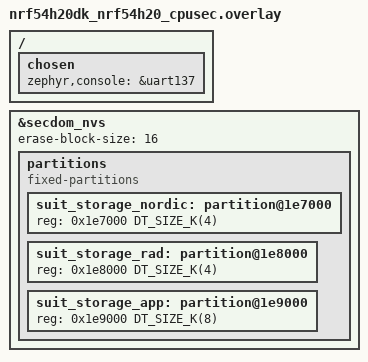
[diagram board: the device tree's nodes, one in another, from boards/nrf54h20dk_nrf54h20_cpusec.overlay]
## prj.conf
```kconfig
#
# Copyright (c) 2022 Nordic Semiconductor ASA
#
# SPDX-License-Identifier: LicenseRef-Nordic-5-Clause
#

CONFIG_ZTEST=y
CONFIG_ZTEST_NEW_API=y

CONFIG_SUIT=y
CONFIG_SUIT_UTILS=y
CONFIG_SUIT_STORAGE=y
CONFIG_SUIT_STORAGE_N_UPDATE_REGIONS=3
CONFIG_SUIT_METADATA=y

CONFIG_ZCBOR=y
CONFIG_ZCBOR_CANONICAL=y

CONFIG_FLASH=y
```

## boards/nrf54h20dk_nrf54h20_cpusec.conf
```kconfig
#
# Copyright (c) 2022 Nordic Semiconductor ASA
#
# SPDX-License-Identifier: LicenseRef-Nordic-5-Clause
#

CONFIG_NULL_POINTER_EXCEPTION_DETECTION_NONE=y
CONFIG_SERIAL=y
CONFIG_CONSOLE=y
CONFIG_UART_CONSOLE=y

# This test does not set 'IS_SECURE_DOMAIN_FW'. Hence, we need to enable the
# bare minimum configurations for running on bare metal Secure Domain.
CONFIG_SECDOM_UNIT_TEST_SUPPORT=y

# Logging and printk is using standard UART.
CONFIG_LOG_MODE_DEFERRED=y
CONFIG_LOG_BACKEND_UART=y
CONFIG_LOG_PRINTK=y
CONFIG_LOG_BUFFER_SIZE=8192
CONFIG_SOC_FLASH_NRF_MRAM_ONE_BYTE_WRITE_ACCESS=y

# nRF54H20 storage uses SHA-256 to protect MPI and NVVs:
CONFIG_SUIT_CRYPTO=y

# Configure MPI, so it matches the test-specific MCI
CONFIG_SUIT_MPI_GENERATE=y
CONFIG_SUIT_MPI_ROOT_CLASS_NAME="test_sample_root"
CONFIG_SUIT_MPI_ROOT_INDEPENDENT_UPDATE=y
CONFIG_SUIT_MPI_ROOT_SIGNATURE_CHECK_ENABLED_ON_UPDATE_AND_BOOT=y
CONFIG_SUIT_MPI_APP_LOCAL_1=y
CONFIG_SUIT_MPI_APP_LOCAL_1_CLASS_NAME="test_sample_app"
CONFIG_SUIT_MPI_APP_LOCAL_1_INDEPENDENT_UPDATE=n
CONFIG_SUIT_MPI_APP_LOCAL_1_SIGNATURE_CHECK_ENABLED_ON_UPDATE_AND_BOOT=y
```

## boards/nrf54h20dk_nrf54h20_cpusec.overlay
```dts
/*
 * Copyright (c) 2022 Nordic Semiconductor ASA
 *
 * SPDX-License-Identifier: LicenseRef-Nordic-5-Clause
 */

/ {
	chosen {
		zephyr,console = &uart137;
	};
};

&secdom_nvs {
	erase-block-size = <16>;

	partitions {
		compatible = "fixed-partitions";
		#address-cells = <1>;
		#size-cells = <1>;

		/* Use the last 32 kB of SecDom SUIT NVM storage. */
		/* Use the first 4kB as area reserved for Secure domain. */
		suit_storage_nordic: partition@1e7000 {
			reg = <0x1e7000 DT_SIZE_K(4)>;
		};

		/* Use the next 4kB as area reserved for Radio domain. */
		suit_storage_rad: partition@1e8000 {
			reg = <0x1e8000 DT_SIZE_K(4)>;
		};

		/* Use the next 8kB as area reserved for Application domain. */
		suit_storage_app: partition@1e9000 {
			reg = <0x1e9000 DT_SIZE_K(8)>;
		};
	};
};
```

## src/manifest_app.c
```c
/*
 * Copyright (c) 2023 Nordic Semiconductor ASA
 *
 * SPDX-License-Identifier: LicenseRef-Nordic-5-Clause
 */

#include <stdint.h>
#include <stddef.h>

/** @brief SUIT envelope generated using the manifest/manifest_app.yaml input file.
 *
 * @details This envelope contains 256-byte random numbers attached as an integrated
 *          payload and fetched directly into the memory-mapped region during install step.
 *          The envelope has been signed using the manifest/key_private.pem key.
 *
 * @note Please use the manifest_common/regenerate.sh script for regenerating payloads.
 */
uint8_t manifest_app_buf[] = {
	0xD8, 0x6B, 0xA4, 0x02, 0x58, 0x7A, 0x82, 0x58, 0x24, 0x82, 0x2F, 0x58, 0x20, 0x26, 0x04,
	0x04, 0xCF, 0x3A, 0xA5, 0x6E, 0xBA, 0x4D, 0xA9, 0xD5, 0xBE, 0xE4, 0x6D, 0x27, 0x33, 0xF3,
	0xD5, 0x4A, 0xD5, 0xE6, 0x72, 0x1E, 0x46, 0xEE, 0x58, 0x93, 0xB6, 0xDC, 0x4D, 0x2C, 0x93,
	0x58, 0x51, 0xD2, 0x84, 0x4A, 0xA2, 0x01, 0x26, 0x04, 0x45, 0x1A, 0x7F, 0xFF, 0xFF, 0xE0,
	0xA0, 0xF6, 0x58, 0x40, 0xE6, 0x16, 0xF7, 0x59, 0x93, 0xF2, 0x48, 0x68, 0x0B, 0xFE, 0x47,
	0x81, 0x10, 0x58, 0x96, 0xCB, 0xAD, 0x0A, 0xE5, 0x9D, 0x82, 0x74, 0xAD, 0x8B, 0x5F, 0x4C,
	0xCD, 0x32, 0xF4, 0x75, 0x27, 0x15, 0xAD, 0x3E, 0xC9, 0x71, 0x08, 0xAB, 0xAF, 0xCA, 0xD9,
	0x9B, 0x9B, 0x5B, 0x48, 0x1B, 0x60, 0x4D, 0xD6, 0xD3, 0xF2, 0x4A, 0x1B, 0x76, 0x56, 0xB6,
	0xEE, 0xF5, 0x41, 0x4D, 0x64, 0x14, 0x9D, 0x34, 0x03, 0x58, 0xDB, 0xA8, 0x01, 0x01, 0x02,
	0x01, 0x03, 0x58, 0x70, 0xA2, 0x02, 0x81, 0x84, 0x44, 0x63, 0x4D, 0x45, 0x4D, 0x41, 0x02,
	0x45, 0x1A, 0x0E, 0x0A, 0xA0, 0x00, 0x45, 0x1A, 0x00, 0x07, 0xF8, 0x00, 0x04, 0x58, 0x56,
	0x86, 0x14, 0xA4, 0x01, 0x50, 0x76, 0x17, 0xDA, 0xA5, 0x71, 0xFD, 0x5A, 0x85, 0x8F, 0x94,
	0xE2, 0x8D, 0x73, 0x5C, 0xE9, 0xF4, 0x02, 0x50, 0x08, 0xC1, 0xB5, 0x99, 0x55, 0xE8, 0x5F,
	0xBC, 0x9E, 0x76, 0x7B, 0xC2, 0x9C, 0xE1, 0xB0, 0x4D, 0x03, 0x58, 0x24, 0x82, 0x2F, 0x58,
	0x20, 0x5F, 0xC3, 0x54, 0xBF, 0x8E, 0x8C, 0x50, 0xFB, 0x4F, 0xBC, 0x2C, 0xFA, 0xEB, 0x04,
	0x53, 0x41, 0xC9, 0x80, 0x6D, 0xEA, 0xBD, 0xCB, 0x41, 0x54, 0xFB, 0x79, 0xCC, 0xA4, 0xF0,
	0xC9, 0x8C, 0x12, 0x0E, 0x19, 0x01, 0x00, 0x01, 0x0F, 0x02, 0x0F, 0x07, 0x43, 0x82, 0x03,
	0x0F, 0x09, 0x43, 0x82, 0x17, 0x02, 0x11, 0x52, 0x86, 0x14, 0xA1, 0x15, 0x69, 0x23, 0x66,
	0x69, 0x6C, 0x65, 0x2E, 0x62, 0x69, 0x6E, 0x15, 0x02, 0x03, 0x0F, 0x17, 0x82, 0x2F, 0x58,
	0x20, 0xD5, 0x91, 0xFC, 0x52, 0x92, 0x3A, 0x98, 0x8F, 0x6C, 0x59, 0x25, 0x62, 0x4E, 0xE5,
	0x27, 0x56, 0xA5, 0x90, 0x5B, 0x6C, 0xC4, 0x6C, 0x4B, 0x6A, 0xF6, 0xBA, 0x68, 0xD5, 0x83,
	0x53, 0xD2, 0x59, 0x05, 0x82, 0x4C, 0x6B, 0x49, 0x4E, 0x53, 0x54, 0x4C, 0x44, 0x5F, 0x4D,
	0x46, 0x53, 0x54, 0x50, 0x08, 0xC1, 0xB5, 0x99, 0x55, 0xE8, 0x5F, 0xBC, 0x9E, 0x76, 0x7B,
	0xC2, 0x9C, 0xE1, 0xB0, 0x4D, 0x17, 0x58, 0x97, 0xA1, 0x84, 0x44, 0x63, 0x4D, 0x45, 0x4D,
	0x41, 0x02, 0x45, 0x1A, 0x0E, 0x0A, 0xA0, 0x00, 0x45, 0x1A, 0x00, 0x07, 0xF8, 0x00, 0xA6,
	0x01, 0x78, 0x18, 0x4E, 0x6F, 0x72, 0x64, 0x69, 0x63, 0x20, 0x53, 0x65, 0x6D, 0x69, 0x63,
	0x6F, 0x6E, 0x64, 0x75, 0x63, 0x74, 0x6F, 0x72, 0x20, 0x41, 0x53, 0x41, 0x02, 0x6F, 0x6E,
	0x52, 0x46, 0x35, 0x34, 0x48, 0x32, 0x30, 0x5F, 0x63, 0x70, 0x75, 0x61, 0x70, 0x70, 0x03,
	0x6E, 0x6E, 0x6F, 0x72, 0x64, 0x69, 0x63, 0x73, 0x65, 0x6D, 0x69, 0x2E, 0x63, 0x6F, 0x6D,
	0x04, 0x78, 0x1D, 0x54, 0x68, 0x65, 0x20, 0x6E, 0x52, 0x46, 0x35, 0x34, 0x48, 0x32, 0x30,
	0x20, 0x61, 0x70, 0x70, 0x6C, 0x69, 0x63, 0x61, 0x74, 0x69, 0x6F, 0x6E, 0x20, 0x63, 0x6F,
	0x72, 0x65, 0x05, 0x78, 0x1A, 0x53, 0x61, 0x6D, 0x70, 0x6C, 0x65, 0x20, 0x61, 0x70, 0x70,
	0x6C, 0x69, 0x63, 0x61, 0x74, 0x69, 0x6F, 0x6E, 0x20, 0x63, 0x6F, 0x72, 0x65, 0x20, 0x46,
	0x57, 0x06, 0x66, 0x76, 0x31, 0x2E, 0x30, 0x2E, 0x30, 0x69, 0x23, 0x66, 0x69, 0x6C, 0x65,
	0x2E, 0x62, 0x69, 0x6E, 0x59, 0x01, 0x00, 0xC7, 0x9C, 0xAB, 0x9D, 0xE8, 0x33, 0x7F, 0x30,
	0x14, 0xEB, 0xAC, 0x02, 0xAF, 0x26, 0x01, 0x5E, 0x80, 0x6D, 0x88, 0xA1, 0xDB, 0x11, 0xA7,
	0x31, 0xDF, 0xA6, 0xEC, 0xCB, 0x9B, 0x48, 0x0D, 0xC8, 0x34, 0x40, 0x6D, 0x30, 0x86, 0x7D,
	0xE8, 0x1B, 0xEC, 0x3C, 0xF5, 0x40, 0xD0, 0x48, 0x18, 0x82, 0x11, 0x9D, 0x7C, 0x3F, 0x6C,
	0xE5, 0x8F, 0xF1, 0xD3, 0x5D, 0xE1, 0x51, 0xF7, 0x6A, 0x0F, 0xAF, 0x0B, 0xBD, 0x4C, 0x5F,
	0xA5, 0x34, 0x1A, 0x66, 0xDB, 0x22, 0xEC, 0x63, 0xED, 0x4B, 0xAB, 0xC7, 0xC8, 0xF7, 0x59,
	0xD8, 0xD6, 0x9E, 0xEC, 0x71, 0x1B, 0x24, 0x20, 0xB9, 0xAE, 0xE1, 0x3B, 0xFC, 0xAE, 0xB8,
	0x77, 0xAC, 0xA4, 0x57, 0x34, 0x97, 0x84, 0x4F, 0x58, 0xD5, 0x68, 0x08, 0x6F, 0xE3, 0x9C,
	0x7E, 0x1B, 0xD7, 0x38, 0x22, 0x98, 0x48, 0xF8, 0x7A, 0x67, 0xB2, 0xD9, 0xAC, 0xC5, 0x34,
	0xC1, 0x27, 0x82, 0x8E, 0x42, 0x79, 0x84, 0x21, 0x37, 0x4C, 0x41, 0x4A, 0x0F, 0xE2, 0x7F,
	0xA0, 0x6A, 0x19, 0x13, 0x3D, 0x52, 0x22, 0x7F, 0xD6, 0x2F, 0x71, 0x12, 0x76, 0xAB, 0x25,
	0x9C, 0xFC, 0x67, 0x08, 0x03, 0x7C, 0xDB, 0x18, 0xE6, 0x45, 0xF8, 0x99, 0xC2, 0x9E, 0x2C,
	0xE3, 0x9B, 0x25, 0xA9, 0x7B, 0x09, 0xFF, 0x00, 0x57, 0x26, 0x08, 0x0A, 0x11, 0x42, 0xCF,
	0x82, 0xA2, 0x6B, 0x2A, 0x99, 0xF9, 0x71, 0x9D, 0x14, 0x19, 0x5C, 0x5C, 0x78, 0x31, 0x60,
	0x42, 0x4A, 0x18, 0x1F, 0xEC, 0x78, 0x6A, 0x9A, 0x7C, 0x4F, 0xCF, 0xE8, 0x5A, 0x29, 0x65,
	0xCD, 0x01, 0x3B, 0x6D, 0x53, 0xBB, 0xC6, 0xDB, 0xDA, 0xD5, 0x8F, 0xF7, 0xF4, 0xD9, 0xB9,
	0x0A, 0x03, 0x4B, 0xFF, 0x33, 0xAB, 0x3B, 0xC5, 0xAF, 0xD0, 0xB8, 0x2C, 0x0F, 0x6A, 0xA9,
	0x11, 0xB0, 0xE8, 0x57, 0x8C, 0x92, 0x53, 0x81};

const size_t manifest_app_len = sizeof(manifest_app_buf);
```

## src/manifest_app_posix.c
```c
/*
 * Copyright (c) 2023 Nordic Semiconductor ASA
 *
 * SPDX-License-Identifier: LicenseRef-Nordic-5-Clause
 */

#include <stdint.h>
#include <stddef.h>

/** @brief SUIT envelope generated using the manifest/manifest_app_posix.yaml input file.
 *
 * @details This envelope contains 256-byte random numbers attached as an integrated
 *          payload and fetched directly into the memory-mapped region during install step.
 *          The envelope has been signed using the manifest/key_private.pem key.
 *
 * @note Please use the manifest_common/regenerate.sh script for regenerating payloads.
 */
uint8_t manifest_app_posix_buf[] = {
	0xD8, 0x6B, 0xA4, 0x02, 0x58, 0x7A, 0x82, 0x58, 0x24, 0x82, 0x2F, 0x58, 0x20, 0xC2, 0xEE,
	0x56, 0x00, 0xE9, 0x08, 0x9C, 0xCD, 0x62, 0xE4, 0xD9, 0x36, 0x00, 0xE2, 0x42, 0xCD, 0xC4,
	0x9F, 0xE4, 0x0F, 0xCC, 0x01, 0x60, 0x7F, 0x4B, 0x40, 0xE3, 0xB4, 0x28, 0x45, 0x53, 0xA8,
	0x58, 0x51, 0xD2, 0x84, 0x4A, 0xA2, 0x01, 0x26, 0x04, 0x45, 0x1A, 0x7F, 0xFF, 0xFF, 0xE0,
	0xA0, 0xF6, 0x58, 0x40, 0xB5, 0x86, 0xB1, 0x56, 0x1C, 0x38, 0x2F, 0x12, 0x99, 0xDC, 0x83,
	0x70, 0xA7, 0x53, 0xE2, 0x68, 0xA9, 0xBA, 0x4E, 0xEA, 0x91, 0xB0, 0xF3, 0x99, 0x4C, 0x9D,
	0xDF, 0x53, 0xDC, 0x9D, 0x22, 0x95, 0x53, 0xC6, 0x70, 0x27, 0xFF, 0x2C, 0xDB, 0xE7, 0x56,
	0x43, 0xAF, 0x40, 0x76, 0x87, 0x2C, 0x28, 0xF0, 0xA6, 0x54, 0x96, 0x4D, 0xA5, 0x49, 0x46,
	0x24, 0x2B, 0x59, 0x07, 0xCB, 0xC0, 0x63, 0x4B, 0x03, 0x58, 0xD9, 0xA8, 0x01, 0x01, 0x02,
	0x01, 0x03, 0x58, 0x6E, 0xA2, 0x02, 0x81, 0x84, 0x44, 0x63, 0x4D, 0x45, 0x4D, 0x41, 0x00,
	0x45, 0x1A, 0x00, 0x08, 0x00, 0x00, 0x43, 0x19, 0x10, 0x00, 0x04, 0x58, 0x56, 0x86, 0x14,
	0xA4, 0x01, 0x50, 0x76, 0x17, 0xDA, 0xA5, 0x71, 0xFD, 0x5A, 0x85, 0x8F, 0x94, 0xE2, 0x8D,
	0x73, 0x5C, 0xE9, 0xF4, 0x02, 0x50, 0x56, 0xDC, 0x9A, 0x14, 0x28, 0xD8, 0x52, 0xD3, 0xBD,
	0x62, 0xE7, 0x7A, 0x08, 0xBC, 0x8B, 0x91, 0x03, 0x58, 0x24, 0x82, 0x2F, 0x58, 0x20, 0x5F,
	0xC3, 0x54, 0xBF, 0x8E, 0x8C, 0x50, 0xFB, 0x4F, 0xBC, 0x2C, 0xFA, 0xEB, 0x04, 0x53, 0x41,
	0xC9, 0x80, 0x6D, 0xEA, 0xBD, 0xCB, 0x41, 0x54, 0xFB, 0x79, 0xCC, 0xA4, 0xF0, 0xC9, 0x8C,
	0x12, 0x0E, 0x19, 0x01, 0x00, 0x01, 0x0F, 0x02, 0x0F, 0x07, 0x43, 0x82, 0x03, 0x0F, 0x09,
	0x43, 0x82, 0x17, 0x02, 0x11, 0x52, 0x86, 0x14, 0xA1, 0x15, 0x69, 0x23, 0x66, 0x69, 0x6C,
	0x65, 0x2E, 0x62, 0x69, 0x6E, 0x15, 0x02, 0x03, 0x0F, 0x17, 0x82, 0x2F, 0x58, 0x20, 0x60,
	0xA8, 0x0D, 0xFD, 0xD4, 0xBF, 0x59, 0x42, 0x7E, 0x92, 0x7C, 0xA6, 0x93, 0x58, 0x63, 0xE1,
	0xF6, 0x04, 0x9A, 0x50, 0xE5, 0x0E, 0xB6, 0xF5, 0x3B, 0x81, 0x67, 0x29, 0x53, 0x14, 0xA7,
	0x9A, 0x05, 0x82, 0x4C, 0x6B, 0x49, 0x4E, 0x53, 0x54, 0x4C, 0x44, 0x5F, 0x4D, 0x46, 0x53,
	0x54, 0x50, 0x56, 0xDC, 0x9A, 0x14, 0x28, 0xD8, 0x52, 0xD3, 0xBD, 0x62, 0xE7, 0x7A, 0x08,
	0xBC, 0x8B, 0x91, 0x17, 0x58, 0x84, 0xA1, 0x84, 0x44, 0x63, 0x4D, 0x45, 0x4D, 0x41, 0x00,
	0x45, 0x1A, 0x00, 0x08, 0x00, 0x00, 0x43, 0x19, 0x10, 0x00, 0xA6, 0x01, 0x78, 0x18, 0x4E,
	0x6F, 0x72, 0x64, 0x69, 0x63, 0x20, 0x53, 0x65, 0x6D, 0x69, 0x63, 0x6F, 0x6E, 0x64, 0x75,
	0x63, 0x74, 0x6F, 0x72, 0x20, 0x41, 0x53, 0x41, 0x02, 0x65, 0x70, 0x6F, 0x73, 0x69, 0x78,
	0x03, 0x6E, 0x6E, 0x6F, 0x72, 0x64, 0x69, 0x63, 0x73, 0x65, 0x6D, 0x69, 0x2E, 0x63, 0x6F,
	0x6D, 0x04, 0x75, 0x54, 0x68, 0x65, 0x20, 0x50, 0x4F, 0x53, 0x49, 0x58, 0x20, 0x61, 0x70,
	0x70, 0x6C, 0x69, 0x63, 0x61, 0x74, 0x69, 0x6F, 0x6E, 0x05, 0x78, 0x1C, 0x53, 0x61, 0x6D,
	0x70, 0x6C, 0x65, 0x20, 0x61, 0x70, 0x70, 0x6C, 0x69, 0x63, 0x61, 0x74, 0x69, 0x6F, 0x6E,
	0x20, 0x66, 0x6F, 0x72, 0x20, 0x50, 0x4F, 0x53, 0x49, 0x58, 0x06, 0x66, 0x76, 0x31, 0x2E,
	0x30, 0x2E, 0x30, 0x69, 0x23, 0x66, 0x69, 0x6C, 0x65, 0x2E, 0x62, 0x69, 0x6E, 0x59, 0x01,
	0x00, 0xC7, 0x9C, 0xAB, 0x9D, 0xE8, 0x33, 0x7F, 0x30, 0x14, 0xEB, 0xAC, 0x02, 0xAF, 0x26,
	0x01, 0x5E, 0x80, 0x6D, 0x88, 0xA1, 0xDB, 0x11, 0xA7, 0x31, 0xDF, 0xA6, 0xEC, 0xCB, 0x9B,
	0x48, 0x0D, 0xC8, 0x34, 0x40, 0x6D, 0x30, 0x86, 0x7D, 0xE8, 0x1B, 0xEC, 0x3C, 0xF5, 0x40,
	0xD0, 0x48, 0x18, 0x82, 0x11, 0x9D, 0x7C, 0x3F, 0x6C, 0xE5, 0x8F, 0xF1, 0xD3, 0x5D, 0xE1,
	0x51, 0xF7, 0x6A, 0x0F, 0xAF, 0x0B, 0xBD, 0x4C, 0x5F, 0xA5, 0x34, 0x1A, 0x66, 0xDB, 0x22,
	0xEC, 0x63, 0xED, 0x4B, 0xAB, 0xC7, 0xC8, 0xF7, 0x59, 0xD8, 0xD6, 0x9E, 0xEC, 0x71, 0x1B,
	0x24, 0x20, 0xB9, 0xAE, 0xE1, 0x3B, 0xFC, 0xAE, 0xB8, 0x77, 0xAC, 0xA4, 0x57, 0x34, 0x97,
	0x84, 0x4F, 0x58, 0xD5, 0x68, 0x08, 0x6F, 0xE3, 0x9C, 0x7E, 0x1B, 0xD7, 0x38, 0x22, 0x98,
	0x48, 0xF8, 0x7A, 0x67, 0xB2, 0xD9, 0xAC, 0xC5, 0x34, 0xC1, 0x27, 0x82, 0x8E, 0x42, 0x79,
	0x84, 0x21, 0x37, 0x4C, 0x41, 0x4A, 0x0F, 0xE2, 0x7F, 0xA0, 0x6A, 0x19, 0x13, 0x3D, 0x52,
	0x22, 0x7F, 0xD6, 0x2F, 0x71, 0x12, 0x76, 0xAB, 0x25, 0x9C, 0xFC, 0x67, 0x08, 0x03, 0x7C,
	0xDB, 0x18, 0xE6, 0x45, 0xF8, 0x99, 0xC2, 0x9E, 0x2C, 0xE3, 0x9B, 0x25, 0xA9, 0x7B, 0x09,
	0xFF, 0x00, 0x57, 0x26, 0x08, 0x0A, 0x11, 0x42, 0xCF, 0x82, 0xA2, 0x6B, 0x2A, 0x99, 0xF9,
	0x71, 0x9D, 0x14, 0x19, 0x5C, 0x5C, 0x78, 0x31, 0x60, 0x42, 0x4A, 0x18, 0x1F, 0xEC, 0x78,
	0x6A, 0x9A, 0x7C, 0x4F, 0xCF, 0xE8, 0x5A, 0x29, 0x65, 0xCD, 0x01, 0x3B, 0x6D, 0x53, 0xBB,
	0xC6, 0xDB, 0xDA, 0xD5, 0x8F, 0xF7, 0xF4, 0xD9, 0xB9, 0x0A, 0x03, 0x4B, 0xFF, 0x33, 0xAB,
	0x3B, 0xC5, 0xAF, 0xD0, 0xB8, 0x2C, 0x0F, 0x6A, 0xA9, 0x11, 0xB0, 0xE8, 0x57, 0x8C, 0x92,
	0x53, 0x81};

const size_t manifest_app_posix_len = sizeof(manifest_app_posix_buf);
```

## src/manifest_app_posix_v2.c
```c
/*
 * Copyright (c) 2024 Nordic Semiconductor ASA
 *
 * SPDX-License-Identifier: LicenseRef-Nordic-5-Clause
 */

#include <stdint.h>
#include <stddef.h>

/** @brief SUIT envelope generated using the manifest/manifest_app_posix_v2.yaml input file.
 *
 * @details This envelope contains 256-byte random numbers attached as an integrated
 *          payload and fetched directly into the memory-mapped region during install step.
 *          The envelope has been signed using the manifest/key_private.pem key.
 *
 * @note Please use the manifest_common/regenerate.sh script for regenerating payloads.
 */
uint8_t manifest_app_posix_v2_buf[] = {
	0xD8, 0x6B, 0xA4, 0x02, 0x58, 0x7A, 0x82, 0x58, 0x24, 0x82, 0x2F, 0x58, 0x20, 0x9F, 0x97,
	0x6D, 0xE9, 0x7D, 0xEE, 0x2C, 0x67, 0xD3, 0xEF, 0xB1, 0x20, 0xA7, 0x6E, 0xDA, 0x0C, 0x98,
	0x9A, 0xD9, 0xC3, 0x14, 0xF9, 0xF7, 0x6F, 0xB4, 0xD6, 0xEB, 0xAF, 0x9E, 0x83, 0x88, 0x5E,
	0x58, 0x51, 0xD2, 0x84, 0x4A, 0xA2, 0x01, 0x26, 0x04, 0x45, 0x1A, 0x7F, 0xFF, 0xFF, 0xE0,
	0xA0, 0xF6, 0x58, 0x40, 0xB2, 0xC4, 0xEE, 0xCC, 0xBE, 0x3B, 0x85, 0xD3, 0x99, 0x4B, 0x2F,
	0xDA, 0xA2, 0x01, 0x49, 0xEE, 0x57, 0x65, 0xE7, 0x1B, 0x2D, 0x48, 0x2B, 0x8B, 0x41, 0xCD,
	0x45, 0x42, 0x6F, 0xBA, 0x9E, 0xC0, 0x97, 0x2D, 0x23, 0x81, 0x76, 0x55, 0xC7, 0xAD, 0x8A,
	0xDA, 0xBD, 0x25, 0x11, 0x15, 0xF7, 0x00, 0x7F, 0x0D, 0x77, 0x45, 0x49, 0xC7, 0x19, 0x74,
	0xF8, 0xDE, 0x25, 0x9E, 0xF1, 0x19, 0x13, 0x45, 0x03, 0x58, 0xD9, 0xA8, 0x01, 0x01, 0x02,
	0x02, 0x03, 0x58, 0x6E, 0xA2, 0x02, 0x81, 0x84, 0x44, 0x63, 0x4D, 0x45, 0x4D, 0x41, 0x00,
	0x45, 0x1A, 0x00, 0x08, 0x00, 0x00, 0x43, 0x19, 0x10, 0x00, 0x04, 0x58, 0x56, 0x86, 0x14,
	0xA4, 0x01, 0x50, 0x76, 0x17, 0xDA, 0xA5, 0x71, 0xFD, 0x5A, 0x85, 0x8F, 0x94, 0xE2, 0x8D,
	0x73, 0x5C, 0xE9, 0xF4, 0x02, 0x50, 0x5B, 0x46, 0x9F, 0xD1, 0x90, 0xEE, 0x53, 0x9C, 0xA3,
	0x18, 0x68, 0x1B, 0x03, 0x69, 0x5E, 0x36, 0x03, 0x58, 0x24, 0x82, 0x2F, 0x58, 0x20, 0x5F,
	0xC3, 0x54, 0xBF, 0x8E, 0x8C, 0x50, 0xFB, 0x4F, 0xBC, 0x2C, 0xFA, 0xEB, 0x04, 0x53, 0x41,
	0xC9, 0x80, 0x6D, 0xEA, 0xBD, 0xCB, 0x41, 0x54, 0xFB, 0x79, 0xCC, 0xA4, 0xF0, 0xC9, 0x8C,
	0x12, 0x0E, 0x19, 0x01, 0x00, 0x01, 0x0F, 0x02, 0x0F, 0x07, 0x43, 0x82, 0x03, 0x0F, 0x09,
	0x43, 0x82, 0x17, 0x02, 0x11, 0x52, 0x86, 0x14, 0xA1, 0x15, 0x69, 0x23, 0x66, 0x69, 0x6C,
	0x65, 0x2E, 0x62, 0x69, 0x6E, 0x15, 0x02, 0x03, 0x0F, 0x17, 0x82, 0x2F, 0x58, 0x20, 0x60,
	0xA8, 0x0D, 0xFD, 0xD4, 0xBF, 0x59, 0x42, 0x7E, 0x92, 0x7C, 0xA6, 0x93, 0x58, 0x63, 0xE1,
	0xF6, 0x04, 0x9A, 0x50, 0xE5, 0x0E, 0xB6, 0xF5, 0x3B, 0x81, 0x67, 0x29, 0x53, 0x14, 0xA7,
	0x9A, 0x05, 0x82, 0x4C, 0x6B, 0x49, 0x4E, 0x53, 0x54, 0x4C, 0x44, 0x5F, 0x4D, 0x46, 0x53,
	0x54, 0x50, 0x5B, 0x46, 0x9F, 0xD1, 0x90, 0xEE, 0x53, 0x9C, 0xA3, 0x18, 0x68, 0x1B, 0x03,
	0x69, 0x5E, 0x36, 0x17, 0x58, 0x84, 0xA1, 0x84, 0x44, 0x63, 0x4D, 0x45, 0x4D, 0x41, 0x00,
	0x45, 0x1A, 0x00, 0x08, 0x00, 0x00, 0x43, 0x19, 0x10, 0x00, 0xA6, 0x01, 0x78, 0x18, 0x4E,
	0x6F, 0x72, 0x64, 0x69, 0x63, 0x20, 0x53, 0x65, 0x6D, 0x69, 0x63, 0x6F, 0x6E, 0x64, 0x75,
	0x63, 0x74, 0x6F, 0x72, 0x20, 0x41, 0x53, 0x41, 0x02, 0x65, 0x70, 0x6F, 0x73, 0x69, 0x78,
	0x03, 0x6E, 0x6E, 0x6F, 0x72, 0x64, 0x69, 0x63, 0x73, 0x65, 0x6D, 0x69, 0x2E, 0x63, 0x6F,
	0x6D, 0x04, 0x75, 0x54, 0x68, 0x65, 0x20, 0x50, 0x4F, 0x53, 0x49, 0x58, 0x20, 0x61, 0x70,
	0x70, 0x6C, 0x69, 0x63, 0x61, 0x74, 0x69, 0x6F, 0x6E, 0x05, 0x78, 0x1C, 0x53, 0x61, 0x6D,
	0x70, 0x6C, 0x65, 0x20, 0x61, 0x70, 0x70, 0x6C, 0x69, 0x63, 0x61, 0x74, 0x69, 0x6F, 0x6E,
	0x20, 0x66, 0x6F, 0x72, 0x20, 0x50, 0x4F, 0x53, 0x49, 0x58, 0x06, 0x66, 0x76, 0x31, 0x2E,
	0x30, 0x2E, 0x30, 0x69, 0x23, 0x66, 0x69, 0x6C, 0x65, 0x2E, 0x62, 0x69, 0x6E, 0x59, 0x01,
	0x00, 0xC7, 0x9C, 0xAB, 0x9D, 0xE8, 0x33, 0x7F, 0x30, 0x14, 0xEB, 0xAC, 0x02, 0xAF, 0x26,
	0x01, 0x5E, 0x80, 0x6D, 0x88, 0xA1, 0xDB, 0x11, 0xA7, 0x31, 0xDF, 0xA6, 0xEC, 0xCB, 0x9B,
	0x48, 0x0D, 0xC8, 0x34, 0x40, 0x6D, 0x30, 0x86, 0x7D, 0xE8, 0x1B, 0xEC, 0x3C, 0xF5, 0x40,
	0xD0, 0x48, 0x18, 0x82, 0x11, 0x9D, 0x7C, 0x3F, 0x6C, 0xE5, 0x8F, 0xF1, 0xD3, 0x5D, 0xE1,
	0x51, 0xF7, 0x6A, 0x0F, 0xAF, 0x0B, 0xBD, 0x4C, 0x5F, 0xA5, 0x34, 0x1A, 0x66, 0xDB, 0x22,
	0xEC, 0x63, 0xED, 0x4B, 0xAB, 0xC7, 0xC8, 0xF7, 0x59, 0xD8, 0xD6, 0x9E, 0xEC, 0x71, 0x1B,
	0x24, 0x20, 0xB9, 0xAE, 0xE1, 0x3B, 0xFC, 0xAE, 0xB8, 0x77, 0xAC, 0xA4, 0x57, 0x34, 0x97,
	0x84, 0x4F, 0x58, 0xD5, 0x68, 0x08, 0x6F, 0xE3, 0x9C, 0x7E, 0x1B, 0xD7, 0x38, 0x22, 0x98,
	0x48, 0xF8, 0x7A, 0x67, 0xB2, 0xD9, 0xAC, 0xC5, 0x34, 0xC1, 0x27, 0x82, 0x8E, 0x42, 0x79,
	0x84, 0x21, 0x37, 0x4C, 0x41, 0x4A, 0x0F, 0xE2, 0x7F, 0xA0, 0x6A, 0x19, 0x13, 0x3D, 0x52,
	0x22, 0x7F, 0xD6, 0x2F, 0x71, 0x12, 0x76, 0xAB, 0x25, 0x9C, 0xFC, 0x67, 0x08, 0x03, 0x7C,
	0xDB, 0x18, 0xE6, 0x45, 0xF8, 0x99, 0xC2, 0x9E, 0x2C, 0xE3, 0x9B, 0x25, 0xA9, 0x7B, 0x09,
	0xFF, 0x00, 0x57, 0x26, 0x08, 0x0A, 0x11, 0x42, 0xCF, 0x82, 0xA2, 0x6B, 0x2A, 0x99, 0xF9,
	0x71, 0x9D, 0x14, 0x19, 0x5C, 0x5C, 0x78, 0x31, 0x60, 0x42, 0x4A, 0x18, 0x1F, 0xEC, 0x78,
	0x6A, 0x9A, 0x7C, 0x4F, 0xCF, 0xE8, 0x5A, 0x29, 0x65, 0xCD, 0x01, 0x3B, 0x6D, 0x53, 0xBB,
	0xC6, 0xDB, 0xDA, 0xD5, 0x8F, 0xF7, 0xF4, 0xD9, 0xB9, 0x0A, 0x03, 0x4B, 0xFF, 0x33, 0xAB,
	0x3B, 0xC5, 0xAF, 0xD0, 0xB8, 0x2C, 0x0F, 0x6A, 0xA9, 0x11, 0xB0, 0xE8, 0x57, 0x8C, 0x92,
	0x53, 0x81};

const size_t manifest_app_posix_v2_len = sizeof(manifest_app_posix_v2_buf);
```

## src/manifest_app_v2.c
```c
/*
 * Copyright (c) 2023 Nordic Semiconductor ASA
 *
 * SPDX-License-Identifier: LicenseRef-Nordic-5-Clause
 */

#include <stdint.h>
#include <stddef.h>

/** @brief SUIT envelope generated using the manifest/manifest_app_v2.yaml input file.
 *
 * @details This envelope contains 256-byte random numbers attached as an integrated
 *          payload and fetched directly into the memory-mapped region during install step.
 *          The envelope has been signed using the manifest/key_private.pem key.
 *
 * @note Please use the manifest_common/regenerate.sh script for regenerating payloads.
 */
uint8_t manifest_app_v2_buf[] = {
	0xD8, 0x6B, 0xA2, 0x02, 0x58, 0x7A, 0x82, 0x58, 0x24, 0x82, 0x2F, 0x58, 0x20, 0x45, 0xCC,
	0xC3, 0x8F, 0xB7, 0xEA, 0x5A, 0x86, 0xC9, 0xEA, 0xA1, 0x73, 0x44, 0x25, 0xDB, 0x4A, 0x43,
	0x90, 0x66, 0x14, 0x88, 0x16, 0x55, 0x08, 0xEA, 0xB5, 0xEA, 0x94, 0x35, 0xD8, 0x49, 0x32,
	0x58, 0x51, 0xD2, 0x84, 0x4A, 0xA2, 0x01, 0x26, 0x04, 0x45, 0x1A, 0x7F, 0xFF, 0xFF, 0xE0,
	0xA0, 0xF6, 0x58, 0x40, 0x7B, 0x03, 0x3F, 0x04, 0xB8, 0xA5, 0xA8, 0xAE, 0x1F, 0x79, 0xC2,
	0xA5, 0xB6, 0x1D, 0x26, 0xD0, 0xF3, 0x5D, 0xBB, 0x93, 0x8B, 0x5C, 0xDF, 0xE8, 0xCD, 0xAE,
	0x61, 0x4C, 0x89, 0x46, 0xC9, 0x01, 0xCB, 0x63, 0x90, 0x7B, 0xD6, 0x37, 0xFB, 0x1E, 0x35,
	0xA7, 0xF6, 0x39, 0xC6, 0xE3, 0x79, 0x70, 0x49, 0x0C, 0x8D, 0x1C, 0x40, 0x58, 0xAD, 0x9A,
	0x61, 0x7E, 0x38, 0xE6, 0xC0, 0xB7, 0x64, 0x8C, 0x03, 0x58, 0xB6, 0xA7, 0x01, 0x01, 0x02,
	0x02, 0x03, 0x58, 0x70, 0xA2, 0x02, 0x81, 0x84, 0x44, 0x63, 0x4D, 0x45, 0x4D, 0x41, 0x02,
	0x45, 0x1A, 0x0E, 0x0A, 0xA0, 0x00, 0x45, 0x1A, 0x00, 0x07, 0xF8, 0x00, 0x04, 0x58, 0x56,
	0x86, 0x14, 0xA4, 0x01, 0x50, 0x76, 0x17, 0xDA, 0xA5, 0x71, 0xFD, 0x5A, 0x85, 0x8F, 0x94,
	0xE2, 0x8D, 0x73, 0x5C, 0xE9, 0xF4, 0x02, 0x50, 0x08, 0xC1, 0xB5, 0x99, 0x55, 0xE8, 0x5F,
	0xBC, 0x9E, 0x76, 0x7B, 0xC2, 0x9C, 0xE1, 0xB0, 0x4D, 0x03, 0x58, 0x24, 0x82, 0x2F, 0x58,
	0x20, 0x5F, 0xC3, 0x54, 0xBF, 0x8E, 0x8C, 0x50, 0xFB, 0x4F, 0xBC, 0x2C, 0xFA, 0xEB, 0x04,
	0x53, 0x41, 0xC9, 0x80, 0x6D, 0xEA, 0xBD, 0xCB, 0x41, 0x54, 0xFB, 0x79, 0xCC, 0xA4, 0xF0,
	0xC9, 0x8C, 0x12, 0x0E, 0x19, 0x01, 0x00, 0x01, 0x0F, 0x02, 0x0F, 0x07, 0x43, 0x82, 0x03,
	0x0F, 0x09, 0x43, 0x82, 0x17, 0x02, 0x11, 0x52, 0x86, 0x14, 0xA1, 0x15, 0x69, 0x23, 0x66,
	0x69, 0x6C, 0x65, 0x2E, 0x62, 0x69, 0x6E, 0x15, 0x02, 0x03, 0x0F, 0x05, 0x82, 0x4C, 0x6B,
	0x49, 0x4E, 0x53, 0x54, 0x4C, 0x44, 0x5F, 0x4D, 0x46, 0x53, 0x54, 0x50, 0x08, 0xC1, 0xB5,
	0x99, 0x55, 0xE8, 0x5F, 0xBC, 0x9E, 0x76, 0x7B, 0xC2, 0x9C, 0xE1, 0xB0, 0x4D};

const size_t manifest_app_v2_len = sizeof(manifest_app_v2_buf);
```

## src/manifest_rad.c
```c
/*
 * Copyright (c) 2023 Nordic Semiconductor ASA
 *
 * SPDX-License-Identifier: LicenseRef-Nordic-5-Clause
 */

#include <stdint.h>
#include <stddef.h>

/** @brief SUIT envelope generated using the manifest/manifest_rad.yaml input file.
 *
 * @details This envelope contains 256-byte random numbers attached as an integrated
 *          payload and fetched directly into the memory-mapped region during install step.
 *          The envelope has been signed using the manifest/key_private.pem key.
 *
 * @note Please use the manifest_common/regenerate.sh script for regenerating payloads.
 */
uint8_t manifest_rad_buf[] = {
	0xD8, 0x6B, 0xA4, 0x02, 0x58, 0x7A, 0x82, 0x58, 0x24, 0x82, 0x2F, 0x58, 0x20, 0x28, 0x0C,
	0xD6, 0x6B, 0x67, 0xA0, 0x0C, 0xC6, 0x35, 0x04, 0xC2, 0x01, 0x65, 0x4B, 0xB4, 0x9E, 0x07,
	0x92, 0xC3, 0xDA, 0x0C, 0x43, 0x6B, 0xDD, 0x45, 0x79, 0x14, 0xCD, 0xF1, 0x96, 0x1B, 0x27,
	0x58, 0x51, 0xD2, 0x84, 0x4A, 0xA2, 0x01, 0x26, 0x04, 0x45, 0x1A, 0x7F, 0xFF, 0xFF, 0xE0,
	0xA0, 0xF6, 0x58, 0x40, 0x48, 0x9A, 0x46, 0xE2, 0x1F, 0xCD, 0x6B, 0xFF, 0x1A, 0x1D, 0x42,
	0x9E, 0xA8, 0x8D, 0x34, 0xF4, 0x33, 0x2B, 0x8F, 0xB9, 0x08, 0x5D, 0xEA, 0xB1, 0x61, 0x86,
	0x74, 0xE4, 0x2C, 0x2C, 0x14, 0x90, 0x8A, 0x62, 0x86, 0xE0, 0x63, 0x25, 0xEF, 0x50, 0x12,
	0xCD, 0x6C, 0x9F, 0x7E, 0xAE, 0x62, 0x71, 0x4F, 0xDE, 0x9D, 0xD6, 0xF7, 0x55, 0xB3, 0x55,
	0xEF, 0xDD, 0x55, 0xDE, 0x69, 0x8A, 0x20, 0x95, 0x03, 0x58, 0xDB, 0xA8, 0x01, 0x01, 0x02,
	0x01, 0x03, 0x58, 0x70, 0xA2, 0x02, 0x81, 0x84, 0x44, 0x63, 0x4D, 0x45, 0x4D, 0x41, 0x03,
	0x45, 0x1A, 0x0E, 0x05, 0x40, 0x00, 0x45, 0x1A, 0x00, 0x05, 0x58, 0x00, 0x04, 0x58, 0x56,
	0x86, 0x14, 0xA4, 0x01, 0x50, 0x76, 0x17, 0xDA, 0xA5, 0x71, 0xFD, 0x5A, 0x85, 0x8F, 0x94,
	0xE2, 0x8D, 0x73, 0x5C, 0xE9, 0xF4, 0x02, 0x50, 0x81, 0x6A, 0xA0, 0xA0, 0xAF, 0x11, 0x5E,
	0xF2, 0x85, 0x8A, 0xFE, 0xB6, 0x68, 0xB2, 0xE9, 0xC9, 0x03, 0x58, 0x24, 0x82, 0x2F, 0x58,
	0x20, 0x5F, 0xC3, 0x54, 0xBF, 0x8E, 0x8C, 0x50, 0xFB, 0x4F, 0xBC, 0x2C, 0xFA, 0xEB, 0x04,
	0x53, 0x41, 0xC9, 0x80, 0x6D, 0xEA, 0xBD, 0xCB, 0x41, 0x54, 0xFB, 0x79, 0xCC, 0xA4, 0xF0,
	0xC9, 0x8C, 0x12, 0x0E, 0x19, 0x01, 0x00, 0x01, 0x0F, 0x02, 0x0F, 0x07, 0x43, 0x82, 0x03,
	0x0F, 0x09, 0x43, 0x82, 0x17, 0x02, 0x11, 0x52, 0x86, 0x14, 0xA1, 0x15, 0x69, 0x23, 0x66,
	0x69, 0x6C, 0x65, 0x2E, 0x62, 0x69, 0x6E, 0x15, 0x02, 0x03, 0x0F, 0x17, 0x82, 0x2F, 0x58,
	0x20, 0x3E, 0xD0, 0x66, 0x23, 0xC1, 0xD6, 0x23, 0x1F, 0x50, 0xCF, 0x53, 0xE5, 0x36, 0xE9,
	0xA5, 0x50, 0x02, 0xD9, 0x74, 0x57, 0x5C, 0x9F, 0x5F, 0x77, 0xF3, 0x22, 0x13, 0x03, 0xE9,
	0x7B, 0x4A, 0x0F, 0x05, 0x82, 0x4C, 0x6B, 0x49, 0x4E, 0x53, 0x54, 0x4C, 0x44, 0x5F, 0x4D,
	0x46, 0x53, 0x54, 0x50, 0x81, 0x6A, 0xA0, 0xA0, 0xAF, 0x11, 0x5E, 0xF2, 0x85, 0x8A, 0xFE,
	0xB6, 0x68, 0xB2, 0xE9, 0xC9, 0x17, 0x58, 0x89, 0xA1, 0x84, 0x44, 0x63, 0x4D, 0x45, 0x4D,
	0x41, 0x03, 0x45, 0x1A, 0x0E, 0x05, 0x40, 0x00, 0x45, 0x1A, 0x00, 0x05, 0x58, 0x00, 0xA6,
	0x01, 0x78, 0x18, 0x4E, 0x6F, 0x72, 0x64, 0x69, 0x63, 0x20, 0x53, 0x65, 0x6D, 0x69, 0x63,
	0x6F, 0x6E, 0x64, 0x75, 0x63, 0x74, 0x6F, 0x72, 0x20, 0x41, 0x53, 0x41, 0x02, 0x6F, 0x6E,
	0x52, 0x46, 0x35, 0x34, 0x48, 0x32, 0x30, 0x5F, 0x63, 0x70, 0x75, 0x72, 0x61, 0x64, 0x03,
	0x6E, 0x6E, 0x6F, 0x72, 0x64, 0x69, 0x63, 0x73, 0x65, 0x6D, 0x69, 0x2E, 0x63, 0x6F, 0x6D,
	0x04, 0x77, 0x54, 0x68, 0x65, 0x20, 0x6E, 0x52, 0x46, 0x35, 0x34, 0x48, 0x32, 0x30, 0x20,
	0x72, 0x61, 0x64, 0x69, 0x6F, 0x20, 0x63, 0x6F, 0x72, 0x65, 0x05, 0x74, 0x53, 0x61, 0x6D,
	0x70, 0x6C, 0x65, 0x20, 0x72, 0x61, 0x64, 0x69, 0x6F, 0x20, 0x63, 0x6F, 0x72, 0x65, 0x20,
	0x46, 0x57, 0x06, 0x66, 0x76, 0x31, 0x2E, 0x30, 0x2E, 0x30, 0x69, 0x23, 0x66, 0x69, 0x6C,
	0x65, 0x2E, 0x62, 0x69, 0x6E, 0x59, 0x01, 0x00, 0xC7, 0x9C, 0xAB, 0x9D, 0xE8, 0x33, 0x7F,
	0x30, 0x14, 0xEB, 0xAC, 0x02, 0xAF, 0x26, 0x01, 0x5E, 0x80, 0x6D, 0x88, 0xA1, 0xDB, 0x11,
	0xA7, 0x31, 0xDF, 0xA6, 0xEC, 0xCB, 0x9B, 0x48, 0x0D, 0xC8, 0x34, 0x40, 0x6D, 0x30, 0x86,
	0x7D, 0xE8, 0x1B, 0xEC, 0x3C, 0xF5, 0x40, 0xD0, 0x48, 0x18, 0x82, 0x11, 0x9D, 0x7C, 0x3F,
	0x6C, 0xE5, 0x8F, 0xF1, 0xD3, 0x5D, 0xE1, 0x51, 0xF7, 0x6A, 0x0F, 0xAF, 0x0B, 0xBD, 0x4C,
	0x5F, 0xA5, 0x34, 0x1A, 0x66, 0xDB, 0x22, 0xEC, 0x63, 0xED, 0x4B, 0xAB, 0xC7, 0xC8, 0xF7,
	0x59, 0xD8, 0xD6, 0x9E, 0xEC, 0x71, 0x1B, 0x24, 0x20, 0xB9, 0xAE, 0xE1, 0x3B, 0xFC, 0xAE,
	0xB8, 0x77, 0xAC, 0xA4, 0x57, 0x34, 0x97, 0x84, 0x4F, 0x58, 0xD5, 0x68, 0x08, 0x6F, 0xE3,
	0x9C, 0x7E, 0x1B, 0xD7, 0x38, 0x22, 0x98, 0x48, 0xF8, 0x7A, 0x67, 0xB2, 0xD9, 0xAC, 0xC5,
	0x34, 0xC1, 0x27, 0x82, 0x8E, 0x42, 0x79, 0x84, 0x21, 0x37, 0x4C, 0x41, 0x4A, 0x0F, 0xE2,
	0x7F, 0xA0, 0x6A, 0x19, 0x13, 0x3D, 0x52, 0x22, 0x7F, 0xD6, 0x2F, 0x71, 0x12, 0x76, 0xAB,
	0x25, 0x9C, 0xFC, 0x67, 0x08, 0x03, 0x7C, 0xDB, 0x18, 0xE6, 0x45, 0xF8, 0x99, 0xC2, 0x9E,
	0x2C, 0xE3, 0x9B, 0x25, 0xA9, 0x7B, 0x09, 0xFF, 0x00, 0x57, 0x26, 0x08, 0x0A, 0x11, 0x42,
	0xCF, 0x82, 0xA2, 0x6B, 0x2A, 0x99, 0xF9, 0x71, 0x9D, 0x14, 0x19, 0x5C, 0x5C, 0x78, 0x31,
	0x60, 0x42, 0x4A, 0x18, 0x1F, 0xEC, 0x78, 0x6A, 0x9A, 0x7C, 0x4F, 0xCF, 0xE8, 0x5A, 0x29,
	0x65, 0xCD, 0x01, 0x3B, 0x6D, 0x53, 0xBB, 0xC6, 0xDB, 0xDA, 0xD5, 0x8F, 0xF7, 0xF4, 0xD9,
	0xB9, 0x0A, 0x03, 0x4B, 0xFF, 0x33, 0xAB, 0x3B, 0xC5, 0xAF, 0xD0, 0xB8, 0x2C, 0x0F, 0x6A,
	0xA9, 0x11, 0xB0, 0xE8, 0x57, 0x8C, 0x92, 0x53, 0x81};

const size_t manifest_rad_len = sizeof(manifest_rad_buf);
```

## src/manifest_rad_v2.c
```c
/*
 * Copyright (c) 2023 Nordic Semiconductor ASA
 *
 * SPDX-License-Identifier: LicenseRef-Nordic-5-Clause
 */

#include <stdint.h>
#include <stddef.h>

/** @brief SUIT envelope generated using the manifest/manifest_rad_v2.yaml input file.
 *
 * @details This envelope contains 256-byte random numbers attached as an integrated
 *          payload and fetched directly into the memory-mapped region during install step.
 *          The envelope has been signed using the manifest/key_private.pem key.
 *
 * @note Please use the manifest_common/regenerate.sh script for regenerating payloads.
 */
uint8_t manifest_rad_v2_buf[] = {
	0xD8, 0x6B, 0xA2, 0x02, 0x58, 0x7A, 0x82, 0x58, 0x24, 0x82, 0x2F, 0x58, 0x20, 0x52, 0xDA,
	0xDD, 0xDF, 0xDA, 0x18, 0xFF, 0x08, 0x14, 0xAA, 0x45, 0x84, 0xC2, 0xE6, 0x71, 0x3B, 0x5F,
	0xD5, 0x8E, 0x23, 0xF3, 0x7C, 0xE8, 0xBB, 0x8A, 0xF6, 0x72, 0xEE, 0x4A, 0xE6, 0x3C, 0x89,
	0x58, 0x51, 0xD2, 0x84, 0x4A, 0xA2, 0x01, 0x26, 0x04, 0x45, 0x1A, 0x7F, 0xFF, 0xFF, 0xE0,
	0xA0, 0xF6, 0x58, 0x40, 0x3F, 0xC1, 0x61, 0x9A, 0xAC, 0x92, 0x30, 0x09, 0x49, 0x26, 0x52,
	0x55, 0xAC, 0x46, 0xC7, 0x57, 0xC4, 0x1D, 0x84, 0x84, 0x2D, 0xA0, 0x5B, 0xEC, 0xAA, 0xF1,
	0x38, 0xB8, 0xB2, 0x5F, 0x90, 0x9B, 0x19, 0xD8, 0x05, 0xF9, 0x42, 0xFD, 0xEF, 0xA7, 0x42,
	0x31, 0xC9, 0x77, 0x34, 0x4D, 0x34, 0x46, 0x7F, 0xDE, 0x9B, 0xED, 0xDF, 0x93, 0xAF, 0x6F,
	0xA5, 0xE3, 0xCF, 0x2F, 0xE6, 0xB4, 0xEF, 0x62, 0x03, 0x58, 0xB6, 0xA7, 0x01, 0x01, 0x02,
	0x02, 0x03, 0x58, 0x70, 0xA2, 0x02, 0x81, 0x84, 0x44, 0x63, 0x4D, 0x45, 0x4D, 0x41, 0x03,
	0x45, 0x1A, 0x0E, 0x05, 0x40, 0x00, 0x45, 0x1A, 0x00, 0x05, 0x58, 0x00, 0x04, 0x58, 0x56,
	0x86, 0x14, 0xA4, 0x01, 0x50, 0x76, 0x17, 0xDA, 0xA5, 0x71, 0xFD, 0x5A, 0x85, 0x8F, 0x94,
	0xE2, 0x8D, 0x73, 0x5C, 0xE9, 0xF4, 0x02, 0x50, 0x81, 0x6A, 0xA0, 0xA0, 0xAF, 0x11, 0x5E,
	0xF2, 0x85, 0x8A, 0xFE, 0xB6, 0x68, 0xB2, 0xE9, 0xC9, 0x03, 0x58, 0x24, 0x82, 0x2F, 0x58,
	0x20, 0x5F, 0xC3, 0x54, 0xBF, 0x8E, 0x8C, 0x50, 0xFB, 0x4F, 0xBC, 0x2C, 0xFA, 0xEB, 0x04,
	0x53, 0x41, 0xC9, 0x80, 0x6D, 0xEA, 0xBD, 0xCB, 0x41, 0x54, 0xFB, 0x79, 0xCC, 0xA4, 0xF0,
	0xC9, 0x8C, 0x12, 0x0E, 0x19, 0x01, 0x00, 0x01, 0x0F, 0x02, 0x0F, 0x07, 0x43, 0x82, 0x03,
	0x0F, 0x09, 0x43, 0x82, 0x17, 0x02, 0x11, 0x52, 0x86, 0x14, 0xA1, 0x15, 0x69, 0x23, 0x66,
	0x69, 0x6C, 0x65, 0x2E, 0x62, 0x69, 0x6E, 0x15, 0x02, 0x03, 0x0F, 0x05, 0x82, 0x4C, 0x6B,
	0x49, 0x4E, 0x53, 0x54, 0x4C, 0x44, 0x5F, 0x4D, 0x46, 0x53, 0x54, 0x50, 0x81, 0x6A, 0xA0,
	0xA0, 0xAF, 0x11, 0x5E, 0xF2, 0x85, 0x8A, 0xFE, 0xB6, 0x68, 0xB2, 0xE9, 0xC9};

const size_t manifest_rad_v2_len = sizeof(manifest_rad_v2_buf);
```

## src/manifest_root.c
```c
/*
 * Copyright (c) 2023 Nordic Semiconductor ASA
 *
 * SPDX-License-Identifier: LicenseRef-Nordic-5-Clause
 */

#include <stdint.h>
#include <stddef.h>

/** @brief SUIT envelope generated using the manifest/manifest_root.yaml input file.
 *
 * @details This envelope contains 256-byte random numbers attached as an integrated
 *          payload and fetched directly into the memory-mapped region during install step.
 *          The envelope has been signed using the manifest/key_private.pem key.
 *
 * @note Please use the manifest_common/regenerate.sh script for regenerating payloads.
 */
uint8_t manifest_root_buf[] = {
	0xD8, 0x6B, 0xA5, 0x02, 0x58, 0x7A, 0x82, 0x58, 0x24, 0x82, 0x2F, 0x58, 0x20, 0x9C, 0x9F,
	0x5F, 0xA1, 0x5E, 0x25, 0xD6, 0x83, 0x2F, 0x50, 0x64, 0x49, 0x08, 0xA9, 0x69, 0x1C, 0xDD,
	0xF1, 0xD3, 0x9E, 0xF4, 0x75, 0xBA, 0x21, 0x38, 0x5E, 0x65, 0x55, 0x26, 0x5C, 0x2D, 0xB0,
	0x58, 0x51, 0xD2, 0x84, 0x4A, 0xA2, 0x01, 0x26, 0x04, 0x45, 0x1A, 0x7F, 0xFF, 0xFF, 0xE0,
	0xA0, 0xF6, 0x58, 0x40, 0xEE, 0xFD, 0xCA, 0x34, 0x1E, 0x61, 0x9E, 0xE9, 0xB4, 0x7E, 0x92,
	0xFD, 0x7C, 0xC2, 0xF6, 0x9D, 0xAE, 0x72, 0x41, 0x3D, 0xF1, 0x58, 0xAA, 0x06, 0x07, 0x33,
	0x56, 0xF2, 0x49, 0x61, 0xF3, 0x70, 0x5B, 0x9D, 0xFA, 0x1B, 0x6A, 0x62, 0x61, 0x99, 0xB5,
	0xBA, 0x38, 0x41, 0x64, 0xD5, 0x5F, 0xAE, 0xEB, 0xE3, 0x92, 0x21, 0x2E, 0x57, 0xED, 0x6B,
	0xC0, 0xBB, 0x8F, 0x6C, 0xF3, 0xB5, 0x1A, 0xD2, 0x03, 0x59, 0x01, 0x94, 0xA8, 0x01, 0x01,
	0x02, 0x01, 0x03, 0x58, 0xB3, 0xA3, 0x02, 0x83, 0x82, 0x4A, 0x69, 0x43, 0x41, 0x4E, 0x44,
	0x5F, 0x4D, 0x46, 0x53, 0x54, 0x41, 0x00, 0x82, 0x4C, 0x6B, 0x49, 0x4E, 0x53, 0x54, 0x4C,
	0x44, 0x5F, 0x4D, 0x46, 0x53, 0x54, 0x50, 0x81, 0x6A, 0xA0, 0xA0, 0xAF, 0x11, 0x5E, 0xF2,
	0x85, 0x8A, 0xFE, 0xB6, 0x68, 0xB2, 0xE9, 0xC9, 0x82, 0x4C, 0x6B, 0x49, 0x4E, 0x53, 0x54,
	0x4C, 0x44, 0x5F, 0x4D, 0x46, 0x53, 0x54, 0x50, 0x08, 0xC1, 0xB5, 0x99, 0x55, 0xE8, 0x5F,
	0xBC, 0x9E, 0x76, 0x7B, 0xC2, 0x9C, 0xE1, 0xB0, 0x4D, 0x04, 0x58, 0x59, 0x8E, 0x0C, 0x01,
	0x14, 0xA2, 0x01, 0x50, 0x76, 0x17, 0xDA, 0xA5, 0x71, 0xFD, 0x5A, 0x85, 0x8F, 0x94, 0xE2,
	0x8D, 0x73, 0x5C, 0xE9, 0xF4, 0x02, 0x50, 0x81, 0x6A, 0xA0, 0xA0, 0xAF, 0x11, 0x5E, 0xF2,
	0x85, 0x8A, 0xFE, 0xB6, 0x68, 0xB2, 0xE9, 0xC9, 0x0C, 0x02, 0x14, 0xA2, 0x01, 0x50, 0x76,
	0x17, 0xDA, 0xA5, 0x71, 0xFD, 0x5A, 0x85, 0x8F, 0x94, 0xE2, 0x8D, 0x73, 0x5C, 0xE9, 0xF4,
	0x02, 0x50, 0x08, 0xC1, 0xB5, 0x99, 0x55, 0xE8, 0x5F, 0xBC, 0x9E, 0x76, 0x7B, 0xC2, 0x9C,
	0xE1, 0xB0, 0x4D, 0x0C, 0x82, 0x01, 0x02, 0x01, 0x0F, 0x02, 0x0F, 0x01, 0xA3, 0x00, 0xA0,
	0x01, 0xA0, 0x02, 0xA0, 0x07, 0x49, 0x86, 0x0C, 0x82, 0x01, 0x02, 0x07, 0x0F, 0x0B, 0x0F,
	0x09, 0x49, 0x86, 0x0C, 0x82, 0x01, 0x02, 0x07, 0x0F, 0x0B, 0x0F, 0x11, 0x58, 0x7B, 0x96,
	0x0C, 0x00, 0x14, 0xA2, 0x15, 0x69, 0x23, 0x72, 0x61, 0x64, 0x2E, 0x73, 0x75, 0x69, 0x74,
	0x03, 0x58, 0x24, 0x82, 0x2F, 0x58, 0x20, 0xC0, 0xDB, 0x75, 0x51, 0x28, 0xE7, 0x72, 0xC5,
	0x8D, 0x2B, 0x4E, 0xDD, 0xC3, 0x94, 0x7D, 0xF8, 0x91, 0x38, 0xAE, 0xA1, 0xD3, 0xDA, 0xB2,
	0xFF, 0x71, 0xB1, 0xF5, 0x45, 0x96, 0x9E, 0x9D, 0x16, 0x15, 0x02, 0x03, 0x0F, 0x07, 0x0F,
	0x0B, 0x0F, 0x14, 0xA2, 0x15, 0x69, 0x23, 0x61, 0x70, 0x70, 0x2E, 0x73, 0x75, 0x69, 0x74,
	0x03, 0x58, 0x24, 0x82, 0x2F, 0x58, 0x20, 0x48, 0xAB, 0x74, 0x29, 0x46, 0xC8, 0x75, 0x32,
	0x91, 0xCF, 0xA9, 0xF8, 0xEB, 0x9F, 0x63, 0x73, 0x7C, 0xFE, 0x78, 0x21, 0x1E, 0xA1, 0x32,
	0x40, 0x58, 0x6F, 0xF2, 0x76, 0xD2, 0x9F, 0x32, 0x6D, 0x15, 0x02, 0x03, 0x0F, 0x07, 0x0F,
	0x0B, 0x0F, 0x17, 0x82, 0x2F, 0x58, 0x20, 0x6B, 0x66, 0xF8, 0x5A, 0xF6, 0xEB, 0xFF, 0xA6,
	0xB3, 0x1E, 0x46, 0x36, 0x1F, 0x18, 0xFC, 0x2A, 0x6B, 0xE9, 0xB6, 0x41, 0x8D, 0x60, 0xC2,
	0x7F, 0x31, 0xEA, 0xF9, 0xA3, 0xE4, 0xCD, 0xC4, 0x65, 0x05, 0x82, 0x4C, 0x6B, 0x49, 0x4E,
	0x53, 0x54, 0x4C, 0x44, 0x5F, 0x4D, 0x46, 0x53, 0x54, 0x50, 0x3F, 0x6A, 0x3A, 0x4D, 0xCD,
	0xFA, 0x58, 0xC5, 0xAC, 0xCE, 0xF9, 0xF5, 0x84, 0xC4, 0x11, 0x24, 0x17, 0x58, 0x80, 0xA1,
	0x82, 0x4A, 0x69, 0x43, 0x41, 0x4E, 0x44, 0x5F, 0x4D, 0x46, 0x53, 0x54, 0x41, 0x00, 0xA6,
	0x01, 0x78, 0x18, 0x4E, 0x6F, 0x72, 0x64, 0x69, 0x63, 0x20, 0x53, 0x65, 0x6D, 0x69, 0x63,
	0x6F, 0x6E, 0x64, 0x75, 0x63, 0x74, 0x6F, 0x72, 0x20, 0x41, 0x53, 0x41, 0x02, 0x68, 0x6E,
	0x52, 0x46, 0x35, 0x34, 0x48, 0x32, 0x30, 0x03, 0x6E, 0x6E, 0x6F, 0x72, 0x64, 0x69, 0x63,
	0x73, 0x65, 0x6D, 0x69, 0x2E, 0x63, 0x6F, 0x6D, 0x04, 0x78, 0x1A, 0x54, 0x68, 0x65, 0x20,
	0x6E, 0x52, 0x46, 0x35, 0x34, 0x48, 0x32, 0x30, 0x20, 0x72, 0x6F, 0x6F, 0x74, 0x20, 0x6D,
	0x61, 0x6E, 0x69, 0x66, 0x65, 0x73, 0x74, 0x05, 0x74, 0x53, 0x61, 0x6D, 0x70, 0x6C, 0x65,
	0x20, 0x72, 0x6F, 0x6F, 0x74, 0x20, 0x6D, 0x61, 0x6E, 0x69, 0x66, 0x65, 0x73, 0x74, 0x06,
	0x66, 0x76, 0x31, 0x2E, 0x30, 0x2E, 0x30, 0x69, 0x23, 0x72, 0x61, 0x64, 0x2E, 0x73, 0x75,
	0x69, 0x74, 0x59, 0x02, 0xF7, 0xD8, 0x6B, 0xA4, 0x02, 0x58, 0x7A, 0x82, 0x58, 0x24, 0x82,
	0x2F, 0x58, 0x20, 0x28, 0x0C, 0xD6, 0x6B, 0x67, 0xA0, 0x0C, 0xC6, 0x35, 0x04, 0xC2, 0x01,
	0x65, 0x4B, 0xB4, 0x9E, 0x07, 0x92, 0xC3, 0xDA, 0x0C, 0x43, 0x6B, 0xDD, 0x45, 0x79, 0x14,
	0xCD, 0xF1, 0x96, 0x1B, 0x27, 0x58, 0x51, 0xD2, 0x84, 0x4A, 0xA2, 0x01, 0x26, 0x04, 0x45,
	0x1A, 0x7F, 0xFF, 0xFF, 0xE0, 0xA0, 0xF6, 0x58, 0x40, 0x48, 0x9A, 0x46, 0xE2, 0x1F, 0xCD,
	0x6B, 0xFF, 0x1A, 0x1D, 0x42, 0x9E, 0xA8, 0x8D, 0x34, 0xF4, 0x33, 0x2B, 0x8F, 0xB9, 0x08,
	0x5D, 0xEA, 0xB1, 0x61, 0x86, 0x74, 0xE4, 0x2C, 0x2C, 0x14, 0x90, 0x8A, 0x62, 0x86, 0xE0,
	0x63, 0x25, 0xEF, 0x50, 0x12, 0xCD, 0x6C, 0x9F, 0x7E, 0xAE, 0x62, 0x71, 0x4F, 0xDE, 0x9D,
	0xD6, 0xF7, 0x55, 0xB3, 0x55, 0xEF, 0xDD, 0x55, 0xDE, 0x69, 0x8A, 0x20, 0x95, 0x03, 0x58,
	0xDB, 0xA8, 0x01, 0x01, 0x02, 0x01, 0x03, 0x58, 0x70, 0xA2, 0x02, 0x81, 0x84, 0x44, 0x63,
	0x4D, 0x45, 0x4D, 0x41, 0x03, 0x45, 0x1A, 0x0E, 0x05, 0x40, 0x00, 0x45, 0x1A, 0x00, 0x05,
	0x58, 0x00, 0x04, 0x58, 0x56, 0x86, 0x14, 0xA4, 0x01, 0x50, 0x76, 0x17, 0xDA, 0xA5, 0x71,
	0xFD, 0x5A, 0x85, 0x8F, 0x94, 0xE2, 0x8D, 0x73, 0x5C, 0xE9, 0xF4, 0x02, 0x50, 0x81, 0x6A,
	0xA0, 0xA0, 0xAF, 0x11, 0x5E, 0xF2, 0x85, 0x8A, 0xFE, 0xB6, 0x68, 0xB2, 0xE9, 0xC9, 0x03,
	0x58, 0x24, 0x82, 0x2F, 0x58, 0x20, 0x5F, 0xC3, 0x54, 0xBF, 0x8E, 0x8C, 0x50, 0xFB, 0x4F,
	0xBC, 0x2C, 0xFA, 0xEB, 0x04, 0x53, 0x41, 0xC9, 0x80, 0x6D, 0xEA, 0xBD, 0xCB, 0x41, 0x54,
	0xFB, 0x79, 0xCC, 0xA4, 0xF0, 0xC9, 0x8C, 0x12, 0x0E, 0x19, 0x01, 0x00, 0x01, 0x0F, 0x02,
	0x0F, 0x07, 0x43, 0x82, 0x03, 0x0F, 0x09, 0x43, 0x82, 0x17, 0x02, 0x11, 0x52, 0x86, 0x14,
	0xA1, 0x15, 0x69, 0x23, 0x66, 0x69, 0x6C, 0x65, 0x2E, 0x62, 0x69, 0x6E, 0x15, 0x02, 0x03,
	0x0F, 0x17, 0x82, 0x2F, 0x58, 0x20, 0x3E, 0xD0, 0x66, 0x23, 0xC1, 0xD6, 0x23, 0x1F, 0x50,
	0xCF, 0x53, 0xE5, 0x36, 0xE9, 0xA5, 0x50, 0x02, 0xD9, 0x74, 0x57, 0x5C, 0x9F, 0x5F, 0x77,
	0xF3, 0x22, 0x13, 0x03, 0xE9, 0x7B, 0x4A, 0x0F, 0x05, 0x82, 0x4C, 0x6B, 0x49, 0x4E, 0x53,
	0x54, 0x4C, 0x44, 0x5F, 0x4D, 0x46, 0x53, 0x54, 0x50, 0x81, 0x6A, 0xA0, 0xA0, 0xAF, 0x11,
	0x5E, 0xF2, 0x85, 0x8A, 0xFE, 0xB6, 0x68, 0xB2, 0xE9, 0xC9, 0x17, 0x58, 0x89, 0xA1, 0x84,
	0x44, 0x63, 0x4D, 0x45, 0x4D, 0x41, 0x03, 0x45, 0x1A, 0x0E, 0x05, 0x40, 0x00, 0x45, 0x1A,
	0x00, 0x05, 0x58, 0x00, 0xA6, 0x01, 0x78, 0x18, 0x4E, 0x6F, 0x72, 0x64, 0x69, 0x63, 0x20,
	0x53, 0x65, 0x6D, 0x69, 0x63, 0x6F, 0x6E, 0x64, 0x75, 0x63, 0x74, 0x6F, 0x72, 0x20, 0x41,
	0x53, 0x41, 0x02, 0x6F, 0x6E, 0x52, 0x46, 0x35, 0x34, 0x48, 0x32, 0x30, 0x5F, 0x63, 0x70,
	0x75, 0x72, 0x61, 0x64, 0x03, 0x6E, 0x6E, 0x6F, 0x72, 0x64, 0x69, 0x63, 0x73, 0x65, 0x6D,
	0x69, 0x2E, 0x63, 0x6F, 0x6D, 0x04, 0x77, 0x54, 0x68, 0x65, 0x20, 0x6E, 0x52, 0x46, 0x35,
	0x34, 0x48, 0x32, 0x30, 0x20, 0x72, 0x61, 0x64, 0x69, 0x6F, 0x20, 0x63, 0x6F, 0x72, 0x65,
	0x05, 0x74, 0x53, 0x61, 0x6D, 0x70, 0x6C, 0x65, 0x20, 0x72, 0x61, 0x64, 0x69, 0x6F, 0x20,
	0x63, 0x6F, 0x72, 0x65, 0x20, 0x46, 0x57, 0x06, 0x66, 0x76, 0x31, 0x2E, 0x30, 0x2E, 0x30,
	0x69, 0x23, 0x66, 0x69, 0x6C, 0x65, 0x2E, 0x62, 0x69, 0x6E, 0x59, 0x01, 0x00, 0xC7, 0x9C,
	0xAB, 0x9D, 0xE8, 0x33, 0x7F, 0x30, 0x14, 0xEB, 0xAC, 0x02, 0xAF, 0x26, 0x01, 0x5E, 0x80,
	0x6D, 0x88, 0xA1, 0xDB, 0x11, 0xA7, 0x31, 0xDF, 0xA6, 0xEC, 0xCB, 0x9B, 0x48, 0x0D, 0xC8,
	0x34, 0x40, 0x6D, 0x30, 0x86, 0x7D, 0xE8, 0x1B, 0xEC, 0x3C, 0xF5, 0x40, 0xD0, 0x48, 0x18,
	0x82, 0x11, 0x9D, 0x7C, 0x3F, 0x6C, 0xE5, 0x8F, 0xF1, 0xD3, 0x5D, 0xE1, 0x51, 0xF7, 0x6A,
	0x0F, 0xAF, 0x0B, 0xBD, 0x4C, 0x5F, 0xA5, 0x34, 0x1A, 0x66, 0xDB, 0x22, 0xEC, 0x63, 0xED,
	0x4B, 0xAB, 0xC7, 0xC8, 0xF7, 0x59, 0xD8, 0xD6, 0x9E, 0xEC, 0x71, 0x1B, 0x24, 0x20, 0xB9,
	0xAE, 0xE1, 0x3B, 0xFC, 0xAE, 0xB8, 0x77, 0xAC, 0xA4, 0x57, 0x34, 0x97, 0x84, 0x4F, 0x58,
	0xD5, 0x68, 0x08, 0x6F, 0xE3, 0x9C, 0x7E, 0x1B, 0xD7, 0x38, 0x22, 0x98, 0x48, 0xF8, 0x7A,
	0x67, 0xB2, 0xD9, 0xAC, 0xC5, 0x34, 0xC1, 0x27, 0x82, 0x8E, 0x42, 0x79, 0x84, 0x21, 0x37,
	0x4C, 0x41, 0x4A, 0x0F, 0xE2, 0x7F, 0xA0, 0x6A, 0x19, 0x13, 0x3D, 0x52, 0x22, 0x7F, 0xD6,
	0x2F, 0x71, 0x12, 0x76, 0xAB, 0x25, 0x9C, 0xFC, 0x67, 0x08, 0x03, 0x7C, 0xDB, 0x18, 0xE6,
	0x45, 0xF8, 0x99, 0xC2, 0x9E, 0x2C, 0xE3, 0x9B, 0x25, 0xA9, 0x7B, 0x09, 0xFF, 0x00, 0x57,
	0x26, 0x08, 0x0A, 0x11, 0x42, 0xCF, 0x82, 0xA2, 0x6B, 0x2A, 0x99, 0xF9, 0x71, 0x9D, 0x14,
	0x19, 0x5C, 0x5C, 0x78, 0x31, 0x60, 0x42, 0x4A, 0x18, 0x1F, 0xEC, 0x78, 0x6A, 0x9A, 0x7C,
	0x4F, 0xCF, 0xE8, 0x5A, 0x29, 0x65, 0xCD, 0x01, 0x3B, 0x6D, 0x53, 0xBB, 0xC6, 0xDB, 0xDA,
	0xD5, 0x8F, 0xF7, 0xF4, 0xD9, 0xB9, 0x0A, 0x03, 0x4B, 0xFF, 0x33, 0xAB, 0x3B, 0xC5, 0xAF,
	0xD0, 0xB8, 0x2C, 0x0F, 0x6A, 0xA9, 0x11, 0xB0, 0xE8, 0x57, 0x8C, 0x92, 0x53, 0x81, 0x69,
	0x23, 0x61, 0x70, 0x70, 0x2E, 0x73, 0x75, 0x69, 0x74, 0x59, 0x03, 0x05, 0xD8, 0x6B, 0xA4,
	0x02, 0x58, 0x7A, 0x82, 0x58, 0x24, 0x82, 0x2F, 0x58, 0x20, 0x26, 0x04, 0x04, 0xCF, 0x3A,
	0xA5, 0x6E, 0xBA, 0x4D, 0xA9, 0xD5, 0xBE, 0xE4, 0x6D, 0x27, 0x33, 0xF3, 0xD5, 0x4A, 0xD5,
	0xE6, 0x72, 0x1E, 0x46, 0xEE, 0x58, 0x93, 0xB6, 0xDC, 0x4D, 0x2C, 0x93, 0x58, 0x51, 0xD2,
	0x84, 0x4A, 0xA2, 0x01, 0x26, 0x04, 0x45, 0x1A, 0x7F, 0xFF, 0xFF, 0xE0, 0xA0, 0xF6, 0x58,
	0x40, 0xE6, 0x16, 0xF7, 0x59, 0x93, 0xF2, 0x48, 0x68, 0x0B, 0xFE, 0x47, 0x81, 0x10, 0x58,
	0x96, 0xCB, 0xAD, 0x0A, 0xE5, 0x9D, 0x82, 0x74, 0xAD, 0x8B, 0x5F, 0x4C, 0xCD, 0x32, 0xF4,
	0x75, 0x27, 0x15, 0xAD, 0x3E, 0xC9, 0x71, 0x08, 0xAB, 0xAF, 0xCA, 0xD9, 0x9B, 0x9B, 0x5B,
	0x48, 0x1B, 0x60, 0x4D, 0xD6, 0xD3, 0xF2, 0x4A, 0x1B, 0x76, 0x56, 0xB6, 0xEE, 0xF5, 0x41,
	0x4D, 0x64, 0x14, 0x9D, 0x34, 0x03, 0x58, 0xDB, 0xA8, 0x01, 0x01, 0x02, 0x01, 0x03, 0x58,
	0x70, 0xA2, 0x02, 0x81, 0x84, 0x44, 0x63, 0x4D, 0x45, 0x4D, 0x41, 0x02, 0x45, 0x1A, 0x0E,
	0x0A, 0xA0, 0x00, 0x45, 0x1A, 0x00, 0x07, 0xF8, 0x00, 0x04, 0x58, 0x56, 0x86, 0x14, 0xA4,
	0x01, 0x50, 0x76, 0x17, 0xDA, 0xA5, 0x71, 0xFD, 0x5A, 0x85, 0x8F, 0x94, 0xE2, 0x8D, 0x73,
	0x5C, 0xE9, 0xF4, 0x02, 0x50, 0x08, 0xC1, 0xB5, 0x99, 0x55, 0xE8, 0x5F, 0xBC, 0x9E, 0x76,
	0x7B, 0xC2, 0x9C, 0xE1, 0xB0, 0x4D, 0x03, 0x58, 0x24, 0x82, 0x2F, 0x58, 0x20, 0x5F, 0xC3,
	0x54, 0xBF, 0x8E, 0x8C, 0x50, 0xFB, 0x4F, 0xBC, 0x2C, 0xFA, 0xEB, 0x04, 0x53, 0x41, 0xC9,
	0x80, 0x6D, 0xEA, 0xBD, 0xCB, 0x41, 0x54, 0xFB, 0x79, 0xCC, 0xA4, 0xF0, 0xC9, 0x8C, 0x12,
	0x0E, 0x19, 0x01, 0x00, 0x01, 0x0F, 0x02, 0x0F, 0x07, 0x43, 0x82, 0x03, 0x0F, 0x09, 0x43,
	0x82, 0x17, 0x02, 0x11, 0x52, 0x86, 0x14, 0xA1, 0x15, 0x69, 0x23, 0x66, 0x69, 0x6C, 0x65,
	0x2E, 0x62, 0x69, 0x6E, 0x15, 0x02, 0x03, 0x0F, 0x17, 0x82, 0x2F, 0x58, 0x20, 0xD5, 0x91,
	0xFC, 0x52, 0x92, 0x3A, 0x98, 0x8F, 0x6C, 0x59, 0x25, 0x62, 0x4E, 0xE5, 0x27, 0x56, 0xA5,
	0x90, 0x5B, 0x6C, 0xC4, 0x6C, 0x4B, 0x6A, 0xF6, 0xBA, 0x68, 0xD5, 0x83, 0x53, 0xD2, 0x59,
	0x05, 0x82, 0x4C, 0x6B, 0x49, 0x4E, 0x53, 0x54, 0x4C, 0x44, 0x5F, 0x4D, 0x46, 0x53, 0x54,
	0x50, 0x08, 0xC1, 0xB5, 0x99, 0x55, 0xE8, 0x5F, 0xBC, 0x9E, 0x76, 0x7B, 0xC2, 0x9C, 0xE1,
	0xB0, 0x4D, 0x17, 0x58, 0x97, 0xA1, 0x84, 0x44, 0x63, 0x4D, 0x45, 0x4D, 0x41, 0x02, 0x45,
	0x1A, 0x0E, 0x0A, 0xA0, 0x00, 0x45, 0x1A, 0x00, 0x07, 0xF8, 0x00, 0xA6, 0x01, 0x78, 0x18,
	0x4E, 0x6F, 0x72, 0x64, 0x69, 0x63, 0x20, 0x53, 0x65, 0x6D, 0x69, 0x63, 0x6F, 0x6E, 0x64,
	0x75, 0x63, 0x74, 0x6F, 0x72, 0x20, 0x41, 0x53, 0x41, 0x02, 0x6F, 0x6E, 0x52, 0x46, 0x35,
	0x34, 0x48, 0x32, 0x30, 0x5F, 0x63, 0x70, 0x75, 0x61, 0x70, 0x70, 0x03, 0x6E, 0x6E, 0x6F,
	0x72, 0x64, 0x69, 0x63, 0x73, 0x65, 0x6D, 0x69, 0x2E, 0x63, 0x6F, 0x6D, 0x04, 0x78, 0x1D,
	0x54, 0x68, 0x65, 0x20, 0x6E, 0x52, 0x46, 0x35, 0x34, 0x48, 0x32, 0x30, 0x20, 0x61, 0x70,
	0x70, 0x6C, 0x69, 0x63, 0x61, 0x74, 0x69, 0x6F, 0x6E, 0x20, 0x63, 0x6F, 0x72, 0x65, 0x05,
	0x78, 0x1A, 0x53, 0x61, 0x6D, 0x70, 0x6C, 0x65, 0x20, 0x61, 0x70, 0x70, 0x6C, 0x69, 0x63,
	0x61, 0x74, 0x69, 0x6F, 0x6E, 0x20, 0x63, 0x6F, 0x72, 0x65, 0x20, 0x46, 0x57, 0x06, 0x66,
	0x76, 0x31, 0x2E, 0x30, 0x2E, 0x30, 0x69, 0x23, 0x66, 0x69, 0x6C, 0x65, 0x2E, 0x62, 0x69,
	0x6E, 0x59, 0x01, 0x00, 0xC7, 0x9C, 0xAB, 0x9D, 0xE8, 0x33, 0x7F, 0x30, 0x14, 0xEB, 0xAC,
	0x02, 0xAF, 0x26, 0x01, 0x5E, 0x80, 0x6D, 0x88, 0xA1, 0xDB, 0x11, 0xA7, 0x31, 0xDF, 0xA6,
	0xEC, 0xCB, 0x9B, 0x48, 0x0D, 0xC8, 0x34, 0x40, 0x6D, 0x30, 0x86, 0x7D, 0xE8, 0x1B, 0xEC,
	0x3C, 0xF5, 0x40, 0xD0, 0x48, 0x18, 0x82, 0x11, 0x9D, 0x7C, 0x3F, 0x6C, 0xE5, 0x8F, 0xF1,
	0xD3, 0x5D, 0xE1, 0x51, 0xF7, 0x6A, 0x0F, 0xAF, 0x0B, 0xBD, 0x4C, 0x5F, 0xA5, 0x34, 0x1A,
	0x66, 0xDB, 0x22, 0xEC, 0x63, 0xED, 0x4B, 0xAB, 0xC7, 0xC8, 0xF7, 0x59, 0xD8, 0xD6, 0x9E,
	0xEC, 0x71, 0x1B, 0x24, 0x20, 0xB9, 0xAE, 0xE1, 0x3B, 0xFC, 0xAE, 0xB8, 0x77, 0xAC, 0xA4,
	0x57, 0x34, 0x97, 0x84, 0x4F, 0x58, 0xD5, 0x68, 0x08, 0x6F, 0xE3, 0x9C, 0x7E, 0x1B, 0xD7,
	0x38, 0x22, 0x98, 0x48, 0xF8, 0x7A, 0x67, 0xB2, 0xD9, 0xAC, 0xC5, 0x34, 0xC1, 0x27, 0x82,
	0x8E, 0x42, 0x79, 0x84, 0x21, 0x37, 0x4C, 0x41, 0x4A, 0x0F, 0xE2, 0x7F, 0xA0, 0x6A, 0x19,
	0x13, 0x3D, 0x52, 0x22, 0x7F, 0xD6, 0x2F, 0x71, 0x12, 0x76, 0xAB, 0x25, 0x9C, 0xFC, 0x67,
	0x08, 0x03, 0x7C, 0xDB, 0x18, 0xE6, 0x45, 0xF8, 0x99, 0xC2, 0x9E, 0x2C, 0xE3, 0x9B, 0x25,
	0xA9, 0x7B, 0x09, 0xFF, 0x00, 0x57, 0x26, 0x08, 0x0A, 0x11, 0x42, 0xCF, 0x82, 0xA2, 0x6B,
	0x2A, 0x99, 0xF9, 0x71, 0x9D, 0x14, 0x19, 0x5C, 0x5C, 0x78, 0x31, 0x60, 0x42, 0x4A, 0x18,
	0x1F, 0xEC, 0x78, 0x6A, 0x9A, 0x7C, 0x4F, 0xCF, 0xE8, 0x5A, 0x29, 0x65, 0xCD, 0x01, 0x3B,
	0x6D, 0x53, 0xBB, 0xC6, 0xDB, 0xDA, 0xD5, 0x8F, 0xF7, 0xF4, 0xD9, 0xB9, 0x0A, 0x03, 0x4B,
	0xFF, 0x33, 0xAB, 0x3B, 0xC5, 0xAF, 0xD0, 0xB8, 0x2C, 0x0F, 0x6A, 0xA9, 0x11, 0xB0, 0xE8,
	0x57, 0x8C, 0x92, 0x53, 0x81};

const size_t manifest_root_len = sizeof(manifest_root_buf);
```

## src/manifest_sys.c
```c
/*
 * Copyright (c) 2023 Nordic Semiconductor ASA
 *
 * SPDX-License-Identifier: LicenseRef-Nordic-5-Clause
 */

#include <stdint.h>
#include <stddef.h>

/** @brief SUIT envelope generated using the manifest/manifest_sys.yaml input file.
 *
 * @details This envelope contains 256-byte random numbers attached as an integrated
 *          payload and fetched directly into the memory-mapped region during install step.
 *          The envelope has been signed using the manifest/key_private.pem key.
 *
 * @note Please use the manifest_common/regenerate.sh script for regenerating payloads.
 */
uint8_t manifest_sys_buf[] = {
	0xD8, 0x6B, 0xA4, 0x02, 0x58, 0x7A, 0x82, 0x58, 0x24, 0x82, 0x2F, 0x58, 0x20, 0x9C, 0xD0,
	0x4A, 0x63, 0x30, 0xDC, 0xCC, 0xBF, 0xD7, 0x41, 0x1F, 0x19, 0x47, 0x6B, 0xF3, 0x9A, 0xD1,
	0x85, 0x62, 0x2F, 0xDD, 0xD4, 0x21, 0x6A, 0x37, 0xD8, 0x30, 0xAC, 0x51, 0x5F, 0x10, 0xA6,
	0x58, 0x51, 0xD2, 0x84, 0x4A, 0xA2, 0x01, 0x26, 0x04, 0x45, 0x1A, 0x7F, 0xFF, 0xFF, 0xE0,
	0xA0, 0xF6, 0x58, 0x40, 0x4F, 0xC6, 0x28, 0x93, 0xC8, 0xEF, 0xE1, 0x21, 0x22, 0x4A, 0x60,
	0x2D, 0x68, 0xF7, 0xA6, 0x25, 0xF2, 0x1F, 0x8A, 0x9B, 0x21, 0x66, 0xAF, 0xCF, 0xD5, 0x6A,
	0x77, 0xA9, 0xD8, 0x8F, 0x3B, 0x16, 0xC5, 0xEA, 0xAF, 0xEB, 0x40, 0xAF, 0xD2, 0x74, 0xDB,
	0x06, 0xF5, 0x13, 0xE0, 0x91, 0xA1, 0x08, 0x73, 0xB1, 0x10, 0x75, 0x0C, 0x6F, 0x9B, 0x23,
	0x21, 0x49, 0x8E, 0x29, 0xA9, 0x4F, 0x1A, 0xDF, 0x03, 0x58, 0xDB, 0xA8, 0x01, 0x01, 0x02,
	0x01, 0x03, 0x58, 0x70, 0xA2, 0x02, 0x81, 0x84, 0x44, 0x63, 0x4D, 0x45, 0x4D, 0x41, 0x0C,
	0x45, 0x1A, 0x0E, 0x04, 0x40, 0x00, 0x45, 0x1A, 0x00, 0x01, 0x00, 0x00, 0x04, 0x58, 0x56,
	0x86, 0x14, 0xA4, 0x01, 0x50, 0x76, 0x17, 0xDA, 0xA5, 0x71, 0xFD, 0x5A, 0x85, 0x8F, 0x94,
	0xE2, 0x8D, 0x73, 0x5C, 0xE9, 0xF4, 0x02, 0x50, 0xC0, 0x8A, 0x25, 0xD7, 0x35, 0xE6, 0x59,
	0x2C, 0xB7, 0xAD, 0x43, 0xAC, 0xC8, 0xD1, 0xD1, 0xC8, 0x03, 0x58, 0x24, 0x82, 0x2F, 0x58,
	0x20, 0x5F, 0xC3, 0x54, 0xBF, 0x8E, 0x8C, 0x50, 0xFB, 0x4F, 0xBC, 0x2C, 0xFA, 0xEB, 0x04,
	0x53, 0x41, 0xC9, 0x80, 0x6D, 0xEA, 0xBD, 0xCB, 0x41, 0x54, 0xFB, 0x79, 0xCC, 0xA4, 0xF0,
	0xC9, 0x8C, 0x12, 0x0E, 0x19, 0x01, 0x00, 0x01, 0x0F, 0x02, 0x0F, 0x07, 0x43, 0x82, 0x03,
	0x0F, 0x09, 0x43, 0x82, 0x17, 0x02, 0x11, 0x52, 0x86, 0x14, 0xA1, 0x15, 0x69, 0x23, 0x66,
	0x69, 0x6C, 0x65, 0x2E, 0x62, 0x69, 0x6E, 0x15, 0x02, 0x03, 0x0F, 0x17, 0x82, 0x2F, 0x58,
	0x20, 0xDA, 0x8F, 0x2A, 0xC4, 0x9B, 0xF7, 0x35, 0x6C, 0xF4, 0xBB, 0xCC, 0x1D, 0x09, 0xAB,
	0x60, 0xEC, 0x2D, 0xF0, 0x35, 0x47, 0xB2, 0xA6, 0xBF, 0x36, 0x5E, 0x11, 0xDA, 0xF3, 0xC9,
	0x05, 0xC3, 0x11, 0x05, 0x82, 0x4C, 0x6B, 0x49, 0x4E, 0x53, 0x54, 0x4C, 0x44, 0x5F, 0x4D,
	0x46, 0x53, 0x54, 0x50, 0xC0, 0x8A, 0x25, 0xD7, 0x35, 0xE6, 0x59, 0x2C, 0xB7, 0xAD, 0x43,
	0xAC, 0xC8, 0xD1, 0xD1, 0xC8, 0x17, 0x58, 0xA3, 0xA1, 0x84, 0x44, 0x63, 0x4D, 0x45, 0x4D,
	0x41, 0x0C, 0x45, 0x1A, 0x0E, 0x04, 0x40, 0x00, 0x45, 0x1A, 0x00, 0x01, 0x00, 0x00, 0xA6,
	0x01, 0x78, 0x18, 0x4E, 0x6F, 0x72, 0x64, 0x69, 0x63, 0x20, 0x53, 0x65, 0x6D, 0x69, 0x63,
	0x6F, 0x6E, 0x64, 0x75, 0x63, 0x74, 0x6F, 0x72, 0x20, 0x41, 0x53, 0x41, 0x02, 0x6F, 0x6E,
	0x52, 0x46, 0x35, 0x34, 0x48, 0x32, 0x30, 0x5F, 0x63, 0x70, 0x75, 0x73, 0x79, 0x73, 0x03,
	0x6E, 0x6E, 0x6F, 0x72, 0x64, 0x69, 0x63, 0x73, 0x65, 0x6D, 0x69, 0x2E, 0x63, 0x6F, 0x6D,
	0x04, 0x78, 0x23, 0x54, 0x68, 0x65, 0x20, 0x6E, 0x52, 0x46, 0x35, 0x34, 0x48, 0x32, 0x30,
	0x20, 0x73, 0x79, 0x73, 0x74, 0x65, 0x6D, 0x20, 0x63, 0x6F, 0x6E, 0x74, 0x72, 0x6F, 0x6C,
	0x6C, 0x65, 0x72, 0x20, 0x63, 0x6F, 0x72, 0x65, 0x05, 0x78, 0x20, 0x53, 0x61, 0x6D, 0x70,
	0x6C, 0x65, 0x20, 0x73, 0x79, 0x73, 0x74, 0x65, 0x6D, 0x20, 0x63, 0x6F, 0x6E, 0x74, 0x72,
	0x6F, 0x6C, 0x6C, 0x65, 0x72, 0x20, 0x63, 0x6F, 0x72, 0x65, 0x20, 0x46, 0x57, 0x06, 0x66,
	0x76, 0x31, 0x2E, 0x30, 0x2E, 0x30, 0x69, 0x23, 0x66, 0x69, 0x6C, 0x65, 0x2E, 0x62, 0x69,
	0x6E, 0x59, 0x01, 0x00, 0xC7, 0x9C, 0xAB, 0x9D, 0xE8, 0x33, 0x7F, 0x30, 0x14, 0xEB, 0xAC,
	0x02, 0xAF, 0x26, 0x01, 0x5E, 0x80, 0x6D, 0x88, 0xA1, 0xDB, 0x11, 0xA7, 0x31, 0xDF, 0xA6,
	0xEC, 0xCB, 0x9B, 0x48, 0x0D, 0xC8, 0x34, 0x40, 0x6D, 0x30, 0x86, 0x7D, 0xE8, 0x1B, 0xEC,
	0x3C, 0xF5, 0x40, 0xD0, 0x48, 0x18, 0x82, 0x11, 0x9D, 0x7C, 0x3F, 0x6C, 0xE5, 0x8F, 0xF1,
	0xD3, 0x5D, 0xE1, 0x51, 0xF7, 0x6A, 0x0F, 0xAF, 0x0B, 0xBD, 0x4C, 0x5F, 0xA5, 0x34, 0x1A,
	0x66, 0xDB, 0x22, 0xEC, 0x63, 0xED, 0x4B, 0xAB, 0xC7, 0xC8, 0xF7, 0x59, 0xD8, 0xD6, 0x9E,
	0xEC, 0x71, 0x1B, 0x24, 0x20, 0xB9, 0xAE, 0xE1, 0x3B, 0xFC, 0xAE, 0xB8, 0x77, 0xAC, 0xA4,
	0x57, 0x34, 0x97, 0x84, 0x4F, 0x58, 0xD5, 0x68, 0x08, 0x6F, 0xE3, 0x9C, 0x7E, 0x1B, 0xD7,
	0x38, 0x22, 0x98, 0x48, 0xF8, 0x7A, 0x67, 0xB2, 0xD9, 0xAC, 0xC5, 0x34, 0xC1, 0x27, 0x82,
	0x8E, 0x42, 0x79, 0x84, 0x21, 0x37, 0x4C, 0x41, 0x4A, 0x0F, 0xE2, 0x7F, 0xA0, 0x6A, 0x19,
	0x13, 0x3D, 0x52, 0x22, 0x7F, 0xD6, 0x2F, 0x71, 0x12, 0x76, 0xAB, 0x25, 0x9C, 0xFC, 0x67,
	0x08, 0x03, 0x7C, 0xDB, 0x18, 0xE6, 0x45, 0xF8, 0x99, 0xC2, 0x9E, 0x2C, 0xE3, 0x9B, 0x25,
	0xA9, 0x7B, 0x09, 0xFF, 0x00, 0x57, 0x26, 0x08, 0x0A, 0x11, 0x42, 0xCF, 0x82, 0xA2, 0x6B,
	0x2A, 0x99, 0xF9, 0x71, 0x9D, 0x14, 0x19, 0x5C, 0x5C, 0x78, 0x31, 0x60, 0x42, 0x4A, 0x18,
	0x1F, 0xEC, 0x78, 0x6A, 0x9A, 0x7C, 0x4F, 0xCF, 0xE8, 0x5A, 0x29, 0x65, 0xCD, 0x01, 0x3B,
	0x6D, 0x53, 0xBB, 0xC6, 0xDB, 0xDA, 0xD5, 0x8F, 0xF7, 0xF4, 0xD9, 0xB9, 0x0A, 0x03, 0x4B,
	0xFF, 0x33, 0xAB, 0x3B, 0xC5, 0xAF, 0xD0, 0xB8, 0x2C, 0x0F, 0x6A, 0xA9, 0x11, 0xB0, 0xE8,
	0x57, 0x8C, 0x92, 0x53, 0x81};

const size_t manifest_sys_len = sizeof(manifest_sys_buf);
```
